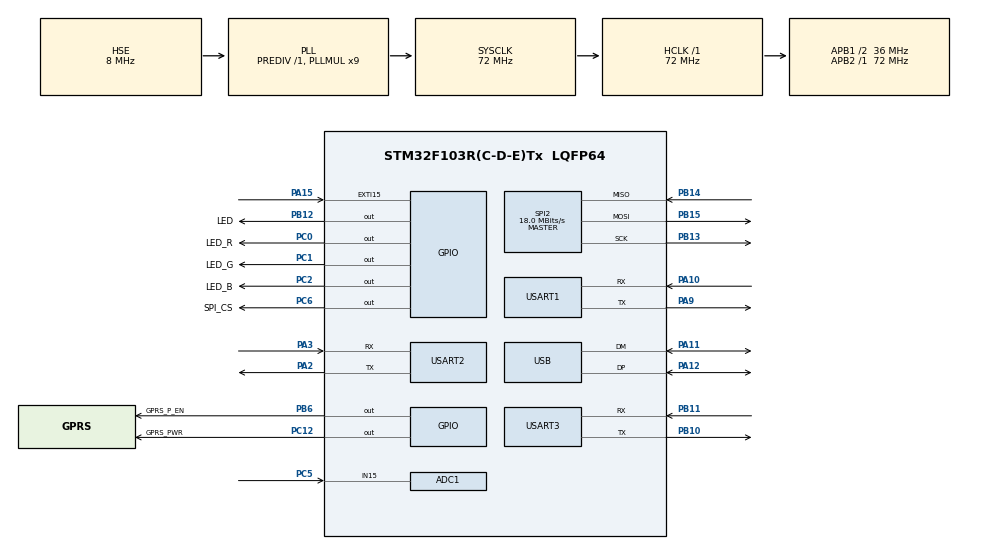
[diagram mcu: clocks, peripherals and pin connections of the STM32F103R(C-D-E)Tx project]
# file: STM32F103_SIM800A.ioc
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ADC1.Channel-0\#ChannelRegularConversion=ADC_CHANNEL_15
ADC1.NbrOfConversionFlag=1
ADC1.Rank-0\#ChannelRegularConversion=1
ADC1.SamplingTime-0\#ChannelRegularConversion=ADC_SAMPLETIME_1CYCLE_5
ADC1.master=1
Mcu.Family=STM32F1
Mcu.Name=STM32F103R(C-D-E)Tx
Mcu.Package=LQFP64
NVIC.PriorityGroup=NVIC_PRIORITYGROUP_4
NVIC.USART1_IRQn=true\:0\:0\:false\:false\:true\:true\:true
NVIC.USART2_IRQn=true\:0\:0\:false\:false\:true\:true\:true
NVIC.USART3_IRQn=true\:0\:0\:false\:false\:true\:true\:true
PA10.Mode=Asynchronous
PA10.Signal=USART1_RX
PA11.Mode=Device
PA11.Signal=USB_DM
PA12.Mode=Device
PA12.Signal=USB_DP
PA15.Signal=GPXTI15
PA2.Mode=Asynchronous
PA2.Signal=USART2_TX
PA3.Mode=Asynchronous
PA3.Signal=USART2_RX
PA9.Mode=Asynchronous
PA9.Signal=USART1_TX
PB10.Mode=Asynchronous
PB10.Signal=USART3_TX
PB11.Mode=Asynchronous
PB11.Signal=USART3_RX
PB12.GPIO_Label=LED
PB12.Signal=GPIO_Output
PB13.Mode=Full_Duplex_Master
PB13.Signal=SPI2_SCK
PB14.Mode=Full_Duplex_Master
PB14.Signal=SPI2_MISO
PB15.Mode=Full_Duplex_Master
PB15.Signal=SPI2_MOSI
PB6.GPIO_Label=GPRS_P_EN
PB6.Signal=GPIO_Output
PC0.GPIO_Label=LED_R
PC0.Signal=GPIO_Output
PC1.GPIO_Label=LED_G
PC1.Signal=GPIO_Output
PC12.GPIO_Label=GPRS_PWR
PC12.Signal=GPIO_Output
PC14-OSC32_IN.Mode=LSE-External-Oscillator
PC14-OSC32_IN.Signal=RCC_OSC32_IN
PC15-OSC32_OUT.Mode=LSE-External-Oscillator
PC15-OSC32_OUT.Signal=RCC_OSC32_OUT
PC2.GPIO_Label=LED_B
PC2.Signal=GPIO_Output
PC5.Signal=ADCx_IN15
PC6.GPIO_Label=SPI_CS
PC6.Signal=GPIO_Output
PD0-OSC_IN.Mode=HSE-External-Oscillator
PD0-OSC_IN.Signal=RCC_OSC_IN
PD1-OSC_OUT.Mode=HSE-External-Oscillator
PD1-OSC_OUT.Signal=RCC_OSC_OUT
ProjectManager.HeapSize=0x200
ProjectManager.StackSize=0x400
ProjectManager.TargetToolchain=EWARM V8.32
RCC.ADCPresc=RCC_ADCPCLK2_DIV6
RCC.AHBFreq_Value=72000000
RCC.APB1CLKDivider=RCC_HCLK_DIV2
RCC.APB1Freq_Value=36000000
RCC.APB1TimFreq_Value=72000000
RCC.APB2Freq_Value=72000000
RCC.APB2TimFreq_Value=72000000
RCC.HCLKFreq_Value=72000000
RCC.PLLMUL=RCC_PLL_MUL9
RCC.SYSCLKFreq_VALUE=72000000
RCC.SYSCLKSource=RCC_SYSCLKSOURCE_PLLCLK
RCC.USBFreq_Value=48000000
RCC.USBPrescaler=RCC_USBCLKSOURCE_PLL_DIV1_5
SH.ADCx_IN15.0=ADC1_IN15,IN15
SPI2.CalculateBaudRate=18.0 MBits/s
SPI2.Direction=SPI_DIRECTION_2LINES
SPI2.Mode=SPI_MODE_MASTER
SPI2.VirtualType=VM_MASTER
USART1.VirtualMode=VM_ASYNC
USART2.VirtualMode=VM_ASYNC
USART3.VirtualMode=VM_ASYNC
VP_SYS_VS_ND.Mode=No_Debug
board=custom

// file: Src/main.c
/* USER CODE BEGIN Header */
/**
  ******************************************************************************
  * @file           : main.c
  * @brief          : Main program body
  ******************************************************************************
  * @attention
  *
  * <h2><center>&copy; Copyright (c) 2020 STMicroelectronics.
  * All rights reserved.</center></h2>
  *
  * This software component is licensed by ST under BSD 3-Clause license,
  * the "License"; You may not use this file except in compliance with the
  * License. You may obtain a copy of the License at:
  *                        opensource.org/licenses/BSD-3-Clause
  *
  ******************************************************************************
  */
/* USER CODE END Header */

#include "main.h"
#include "adc.h"
#include "spi.h"
#include "usart.h"
#include "usb.h"
#include "gpio.h"

#include "stdio.h"
#include "cmsis_os.h"

int fputc(int ch, FILE *f)
{
  if (ch == '\n') {
    HAL_UART_Transmit(&huart1, (void *)"\r", 1,30000);
  }
  HAL_UART_Transmit(&huart1, (uint8_t *)&ch, 1, 0xFFFF);
  return ch;
}

int _write(int fd, char *ptr, int len)
{
    (void)HAL_UART_Transmit(&huart1, (uint8_t *)ptr, len, 0xFFFF);
    return len;
}

int fgetc(FILE *f)
{
  /* Place your implementation of fgetc here */
  /* e.g. readwrite a character to the USART2 and Loop until the end of transmission */
  uint8_t ch = 0;
  HAL_UART_Receive(&huart1, &ch, 1,30000);
  return ch;
}

void SystemClock_Config(void);

/* USER CODE BEGIN 0 */
#define APPLICATION_TASK_STK_SIZE       4096

extern void application_entry(void *arg);
osThreadDef(application_entry, osPriorityNormal, 1, APPLICATION_TASK_STK_SIZE);

__weak void application_entry(void *arg)
{
    while (1) {
        printf("This is a demo task,please use your task entry!\r\n");
        tos_task_delay(1000);
    }
}
/* USER CODE END 0 */

int main(void)
{

  /* MCU Configuration--------------------------------------------------------*/

  /* Reset of all peripherals, Initializes the Flash interface and the Systick. */
  HAL_Init();

  /* Configure the system clock */
  SystemClock_Config();

  /* Initialize all configured peripherals */
  MX_GPIO_Init();
  MX_USART1_UART_Init();
  MX_USART2_UART_Init();
  MX_USART3_UART_Init();
  MX_SPI2_Init();
  MX_USB_PCD_Init();
  MX_ADC1_Init();

    printf("welcome to Tencent TOS Tiny\r\n");
    osKernelInitialize();
    osThreadCreate(osThread(application_entry), NULL);
    osKernelStart();
}

void SystemClock_Config(void)
{
  RCC_OscInitTypeDef RCC_OscInitStruct = {0};
  RCC_ClkInitTypeDef RCC_ClkInitStruct = {0};
  RCC_PeriphCLKInitTypeDef PeriphClkInit = {0};

  /** Initializes the CPU, AHB and APB busses clocks
  */
  RCC_OscInitStruct.OscillatorType = RCC_OSCILLATORTYPE_HSE;
  RCC_OscInitStruct.HSEState = RCC_HSE_ON;
  RCC_OscInitStruct.HSEPredivValue = RCC_HSE_PREDIV_DIV1;
  RCC_OscInitStruct.HSIState = RCC_HSI_ON;
  RCC_OscInitStruct.PLL.PLLState = RCC_PLL_ON;
  RCC_OscInitStruct.PLL.PLLSource = RCC_PLLSOURCE_HSE;
  RCC_OscInitStruct.PLL.PLLMUL = RCC_PLL_MUL9;
  if (HAL_RCC_OscConfig(&RCC_OscInitStruct) != HAL_OK)
  {
    Error_Handler();
  }
  /** Initializes the CPU, AHB and APB busses clocks
  */
  RCC_ClkInitStruct.ClockType = RCC_CLOCKTYPE_HCLK|RCC_CLOCKTYPE_SYSCLK
                              |RCC_CLOCKTYPE_PCLK1|RCC_CLOCKTYPE_PCLK2;
  RCC_ClkInitStruct.SYSCLKSource = RCC_SYSCLKSOURCE_PLLCLK;
  RCC_ClkInitStruct.AHBCLKDivider = RCC_SYSCLK_DIV1;
  RCC_ClkInitStruct.APB1CLKDivider = RCC_HCLK_DIV2;
  RCC_ClkInitStruct.APB2CLKDivider = RCC_HCLK_DIV1;

  if (HAL_RCC_ClockConfig(&RCC_ClkInitStruct, FLASH_LATENCY_2) != HAL_OK)
  {
    Error_Handler();
  }
  PeriphClkInit.PeriphClockSelection = RCC_PERIPHCLK_ADC|RCC_PERIPHCLK_USB;
  PeriphClkInit.AdcClockSelection = RCC_ADCPCLK2_DIV6;
  PeriphClkInit.UsbClockSelection = RCC_USBCLKSOURCE_PLL_DIV1_5;
  if (HAL_RCCEx_PeriphCLKConfig(&PeriphClkInit) != HAL_OK)
  {
    Error_Handler();
  }
}

void Error_Handler(void)
{
}

/************************ (C) COPYRIGHT STMicroelectronics *****END OF FILE****/
